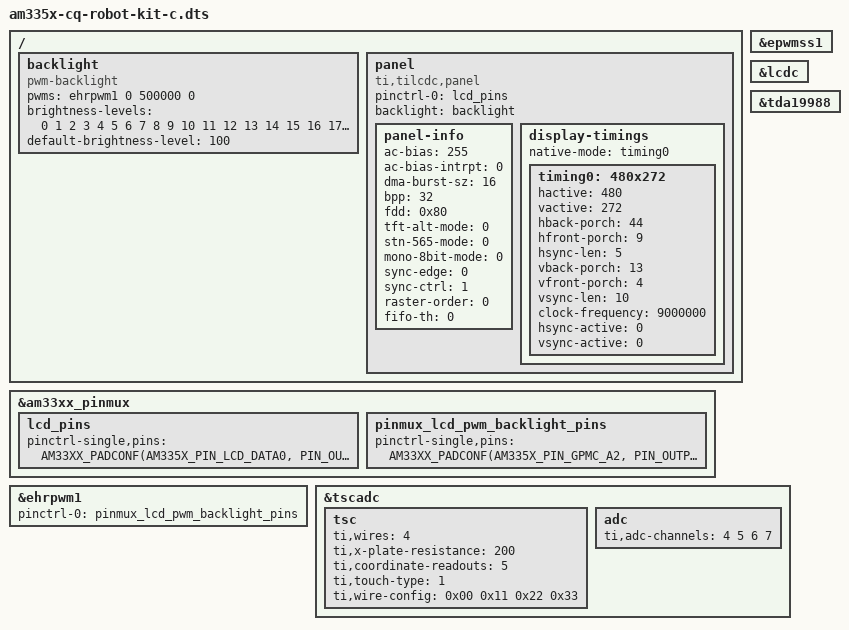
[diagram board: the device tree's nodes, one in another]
// SPDX-License-Identifier: GPL-2.0-only
/*
 * Copyright (C) 2012 Texas Instruments Incorporated - https://www.ti.com/
 */
/dts-v1/;

#include "am335x-boneblack.dts"

/ {
	backlight: backlight {
		compatible  = "pwm-backlight";
		status = "okay";
		pwms = <&ehrpwm1 0 500000 0>;
		brightness-levels = < 0  1  2  3  4  5  6  7  8  9
				     10 11 12 13 14 15 16 17 18 19
				     20 21 22 23 24 25 26 27 28 29
				     30 31 32 33 34 35 36 37 38 39
				     40 41 42 43 44 45 46 47 48 49
				     50 51 52 53 54 55 56 57 58 59
				     60 61 62 63 64 65 66 67 68 69
				     70 71 72 73 74 75 76 77 78 79
				     80 81 82 83 84 85 86 87 88 89
				     90 91 92 93 94 95 96 97 98 99
				    100>;
		default-brightness-level = <100>;
	};

	panel {
		compatible = "ti,tilcdc,panel";
		status = "okay";
		pinctrl-names = "default";
		pinctrl-0 = <&lcd_pins>;
		backlight = <&backlight>;

		panel-info {
			ac-bias           = <255>;
			ac-bias-intrpt    = <0>;
			dma-burst-sz      = <16>;
			bpp               = <32>;
			fdd               = <0x80>;
			tft-alt-mode      = <0>;
			stn-565-mode      = <0>;
			mono-8bit-mode    = <0>;
			sync-edge         = <0>;
			sync-ctrl         = <1>;
			raster-order      = <0>;
			fifo-th           = <0>;
		};

		display-timings {
			native-mode = <&timing0>;
			timing0: 480x272 {
				hactive         = <480>;
				vactive         = <272>;
				hback-porch     = <44>;
				hfront-porch    = <9>;
				hsync-len       = <5>;
				vback-porch     = <13>;
				vfront-porch    = <4>;
				vsync-len       = <10>;
				clock-frequency = <9000000>;
				hsync-active    = <0>;
				vsync-active    = <0>;
			};
		};
	};
};

&am33xx_pinmux {

	lcd_pins: lcd_pins {
		pinctrl-single,pins = <
			AM33XX_PADCONF(AM335X_PIN_LCD_DATA0, PIN_OUTPUT, MUX_MODE0)
			AM33XX_PADCONF(AM335X_PIN_LCD_DATA1, PIN_OUTPUT, MUX_MODE0)
			AM33XX_PADCONF(AM335X_PIN_LCD_DATA2, PIN_OUTPUT, MUX_MODE0)
			AM33XX_PADCONF(AM335X_PIN_LCD_DATA3, PIN_OUTPUT, MUX_MODE0)
			AM33XX_PADCONF(AM335X_PIN_LCD_DATA4, PIN_OUTPUT, MUX_MODE0)
			AM33XX_PADCONF(AM335X_PIN_LCD_DATA5, PIN_OUTPUT, MUX_MODE0)
			AM33XX_PADCONF(AM335X_PIN_LCD_DATA6, PIN_OUTPUT, MUX_MODE0)
			AM33XX_PADCONF(AM335X_PIN_LCD_DATA7, PIN_OUTPUT, MUX_MODE0)
			AM33XX_PADCONF(AM335X_PIN_LCD_DATA8, PIN_OUTPUT, MUX_MODE0)
			AM33XX_PADCONF(AM335X_PIN_LCD_DATA9, PIN_OUTPUT, MUX_MODE0)
			AM33XX_PADCONF(AM335X_PIN_LCD_DATA10, PIN_OUTPUT, MUX_MODE0)
			AM33XX_PADCONF(AM335X_PIN_LCD_DATA11, PIN_OUTPUT, MUX_MODE0)
			AM33XX_PADCONF(AM335X_PIN_LCD_DATA12, PIN_OUTPUT, MUX_MODE0)
			AM33XX_PADCONF(AM335X_PIN_LCD_DATA13, PIN_OUTPUT, MUX_MODE0)
			AM33XX_PADCONF(AM335X_PIN_LCD_DATA14, PIN_OUTPUT, MUX_MODE0)
			AM33XX_PADCONF(AM335X_PIN_LCD_DATA15, PIN_OUTPUT, MUX_MODE0)
			AM33XX_PADCONF(AM335X_PIN_LCD_VSYNC, PIN_OUTPUT_PULLDOWN, MUX_MODE0)
			AM33XX_PADCONF(AM335X_PIN_LCD_HSYNC, PIN_OUTPUT_PULLDOWN, MUX_MODE0)
			AM33XX_PADCONF(AM335X_PIN_LCD_PCLK, PIN_OUTPUT_PULLDOWN, MUX_MODE0)
			AM33XX_PADCONF(AM335X_PIN_LCD_AC_BIAS_EN, PIN_OUTPUT_PULLDOWN, MUX_MODE0)
		>;
	};

	pinmux_lcd_pwm_backlight_pins: pinmux_lcd_pwm_backlight_pins {
		pinctrl-single,pins = <
			AM33XX_PADCONF(AM335X_PIN_GPMC_A2, PIN_OUTPUT, MUX_MODE6)
		>;
	};
};

&epwmss1 {
	status = "okay";
};

&ehrpwm1 {
	status = "okay";
	pinctrl-names = "default";
	pinctrl-0 = <&pinmux_lcd_pwm_backlight_pins>;
};

&lcdc {
	status = "okay";

	/delete-node/ port;
};

&tda19988 {
	/delete-node/ ports;
};

&tscadc {
	status = "okay";

	tsc {
		ti,wires = <4>;
		ti,x-plate-resistance = <200>;
		ti,coordinate-readouts = <5>;
		ti,touch-type = <1>;
		ti,wire-config = <0x00 0x11 0x22 0x33>;
	};

	adc {
		ti,adc-channels = <4 5 6 7>;
	};
};
